# PIC32MZ1025W104132 register map
Vendor: Microchip
Registers are 32-bit, read-write, no defined reset value unless marked. A register's access mark holds for its fields unless they carry their own. Addresses are absolute, and some are shared; only a register's first bit layout is shown; [hi:lo] are bit positions; {n}, {i} and the like mark numbered series; 'fields as' and 'values as' point back to an identical list.

## TMR1
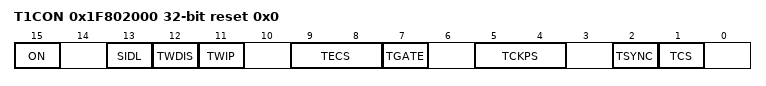
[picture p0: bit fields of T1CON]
0x1F802000 T1CON reset 0x0
  [15] ON, [13] SIDL, [12] TWDIS, [11] TWIP, [9:8] TECS, [7] TGATE, [5:4] TCKPS, [2] TSYNC, [1] TCS
0x1F802010 TMR1 reset 0x0
0x1F802020 PR1 reset 0xFFFF

## TMR2
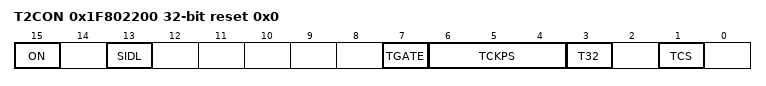
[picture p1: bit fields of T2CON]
0x1F802200 T2CON reset 0x0
  [15] ON, [13] SIDL, [7] TGATE, [6:4] TCKPS, [3] T32, [1] TCS
0x1F802210 TMR2 reset 0x0
0x1F802220 PR2 reset 0xFFFF

## TMR3
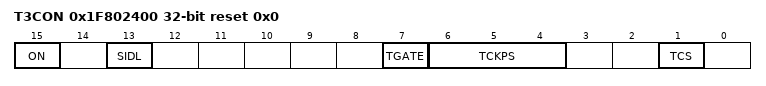
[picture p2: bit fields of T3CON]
0x1F802400 T3CON reset 0x0
  [15] ON, [13] SIDL, [7] TGATE, [6:4] TCKPS, [1] TCS
0x1F802410 TMR3 reset 0x0
0x1F802420 PR3 reset 0xFFFF

## TMR4
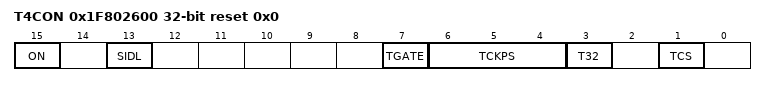
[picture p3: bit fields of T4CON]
0x1F802600 T4CON reset 0x0
  [15] ON, [13] SIDL, [7] TGATE, [6:4] TCKPS, [3] T32, [1] TCS
0x1F802610 TMR4 reset 0x0
0x1F802620 PR4 reset 0xFFFF

## TMR5
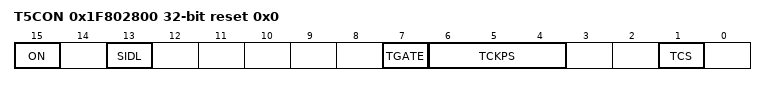
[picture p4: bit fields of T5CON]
0x1F802800 T5CON reset 0x0
  [15] ON, [13] SIDL, [7] TGATE, [6:4] TCKPS, [1] TCS
0x1F802810 TMR5 reset 0x0
0x1F802820 PR5 reset 0xFFFF

## TMR6
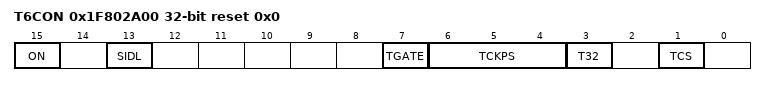
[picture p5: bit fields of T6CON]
0x1F802A00 T6CON reset 0x0
  [15] ON, [13] SIDL, [7] TGATE, [6:4] TCKPS, [3] T32, [1] TCS
0x1F802A10 TMR6 reset 0x0
0x1F802A20 PR6 reset 0xFFFF

## TMR7
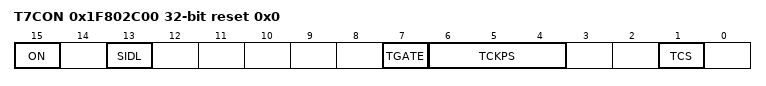
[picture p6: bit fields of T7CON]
0x1F802C00 T7CON reset 0x0
  [15] ON, [13] SIDL, [7] TGATE, [6:4] TCKPS, [1] TCS
0x1F802C10 TMR7 reset 0x0
0x1F802C20 PR7 reset 0xFFFF

## INT
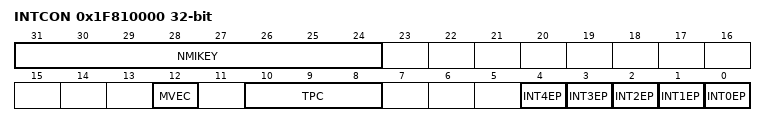
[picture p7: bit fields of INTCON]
0x1F810000 INTCON — (power-on value xxxxxxxx---------x-0-000---00000)
  [31:24] NMIKEY wo, [12] MVEC, [10:8] TPC, [n] INT{n}EP (n=0..4)
{0x1F810540+4i} OFF{i:03} reset 0x0 (i=0..24)
  [17:1] VOFF
{0x1F810540+4i} OFF{i:03} reset 0x0 (i=30..44)
  [17:1] VOFF
0x1F8105F4 OFF045 — (power-on value --------------xxxxxxxxxxxxxxxxx-)
  [17:1] VOFF
0x1F8105F8 OFF046 reset 0x0
  [17:1] VOFF
0x1F8105FC OFF047 reset 0x0
  [17:1] VOFF
{0x1F810540+4i} OFF{i:03} reset 0x0 (i=53..57)
  [17:1] VOFF
0x1F810628 OFF058 — (power-on value --------------xxxxxxxxxxxxxxxxx-)
  [17:1] VOFF
{0x1F810540+4i} OFF{i:03} reset 0x0 (i=59..64)
  [17:1] VOFF
{0x1F810540+4i} OFF{i:03} reset 0x0 (i=68..76)
  [17:1] VOFF
0x1F810680 OFF080 reset 0x0
  [17:1] VOFF
{0x1F810540+4i} OFF{i:03} reset 0x0 (i=83..92)
  [17:1] VOFF
{0x1F810540+4i} OFF{i:03} reset 0x0 (i=94..97)
  [17:1] VOFF
{0x1F810540+4i} OFF{i} reset 0x0 (i=100..104)
  [17:1] VOFF
{0x1F810540+4i} OFF{i} reset 0x0 (i=106..129)
  [17:1] VOFF
{0x1F810540+4i} OFF{i} reset 0x0 (i=142..145)
  [17:1] VOFF
0x1F810798 OFF150 reset 0x0
  [17:1] VOFF
{0x1F810540+4i} OFF{i} reset 0x0 (i=152..157)
  [17:1] VOFF
{0x1F810540+4i} OFF{i} reset 0x0 (i=162..168)
  [17:1] VOFF

## dma_bvci
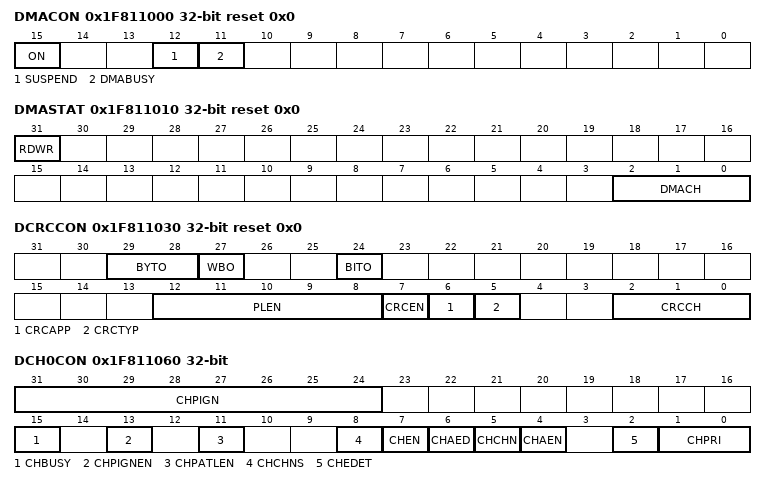
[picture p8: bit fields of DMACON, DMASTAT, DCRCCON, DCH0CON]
0x1F811000 DMACON reset 0x0
  [15] ON, [12] SUSPEND, [11] DMABUSY
0x1F811010 DMASTAT ro reset 0x0
  [31] RDWR, [2:0] DMACH
0x1F811020 DMAADDR ro reset 0x0
0x1F811030 DCRCCON reset 0x0
  [29:28] BYTO, [27] WBO, [24] BITO, [12:8] PLEN, [7] CRCEN, [6] CRCAPP, [5] CRCTYP, [2:0] CRCCH
0x1F811040 DCRCDATA reset 0x0
0x1F811050 DCRCXOR reset 0x0
0x1F811060 DCH0CON — (power-on value xxxxxxxx--------0-0-0--00000-000)
  [31:24] CHPIGN, [15] CHBUSY, [13] CHPIGNEN, [11] CHPATLEN, [8] CHCHNS, [7] CHEN, [6] CHAED, [5] CHCHN, [4] CHAEN, [2] CHEDET ro, [1:0] CHPRI
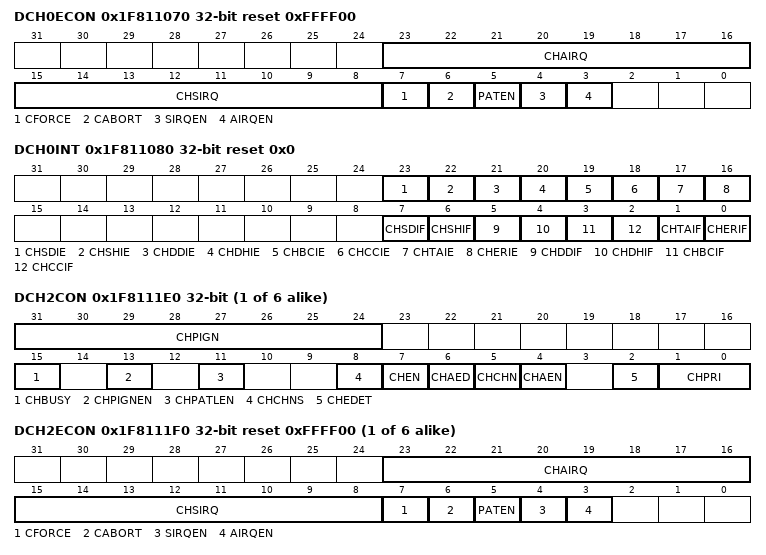
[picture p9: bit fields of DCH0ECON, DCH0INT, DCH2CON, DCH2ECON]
0x1F811070 DCH0ECON reset 0xFFFF00
  [23:16] CHAIRQ, [15:8] CHSIRQ, [7] CFORCE, [6] CABORT, [5] PATEN, [4] SIRQEN, [3] AIRQEN
0x1F811080 DCH0INT reset 0x0
  [23] CHSDIE, [22] CHSHIE, [21] CHDDIE, [20] CHDHIE, [19] CHBCIE, [18] CHCCIE, [17] CHTAIE, [16] CHERIE, [7] CHSDIF, [6] CHSHIF, [5] CHDDIF, [4] CHDHIF, [3] CHBCIF, [2] CHCCIF, [1] CHTAIF, [0] CHERIF
0x1F811090 DCH0SSA — (power-on value xxxxxxxxxxxxxxxxxxxxxxxxxxxxxxxx)
  [31:0] CHSSA
0x1F8110A0 DCH0DSA — (power-on value xxxxxxxxxxxxxxxxxxxxxxxxxxxxxxxx)
  [31:0] CHDSA
0x1F8110B0 DCH0SSIZ — (power-on value ----------------xxxxxxxxxxxxxxxx)
  [15:0] CHSSIZ
0x1F8110C0 DCH0DSIZ — (power-on value ----------------xxxxxxxxxxxxxxxx)
  [15:0] CHDSIZ
0x1F8110D0 DCH0SPTR reset 0x0
  [15:0] CHSPTR
0x1F8110E0 DCH0DPTR reset 0x0
  [15:0] CHDPTR
0x1F8110F0 DCH0CSIZ — (power-on value ----------------xxxxxxxxxxxxxxxx)
  [15:0] CHCSIZ
0x1F811100 DCH0CPTR reset 0x0
  [15:0] CHCPTR
0x1F811110 DCH0DAT — (power-on value ----------------xxxxxxxxxxxxxxxx)
  [15:0] CHPDAT
{0x1F811060+0xC0*i} DCH{i}CON (i=2..7) — (power-on value xxxxxxxx--------0-0-0--00000-000)
  fields as DCH0CON
{0x1F811070+0xC0*i} DCH{i}ECON reset 0xFFFF00 (i=2..7)
  fields as DCH0ECON
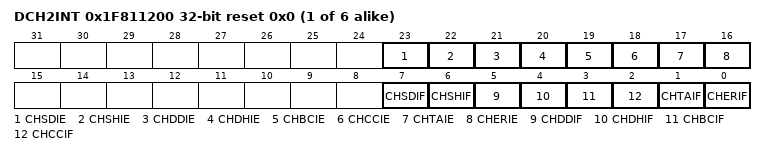
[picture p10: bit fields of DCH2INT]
{0x1F811080+0xC0*i} DCH{i}INT reset 0x0 (i=2..7)
  fields as DCH0INT
{0x1F811090+0xC0*i} DCH{i}SSA (i=2..7) — (power-on value xxxxxxxxxxxxxxxxxxxxxxxxxxxxxxxx)
  [31:0] CHSSA
{0x1F8110A0+0xC0*i} DCH{i}DSA (i=2..7) — (power-on value xxxxxxxxxxxxxxxxxxxxxxxxxxxxxxxx)
  [31:0] CHDSA
{0x1F8110B0+0xC0*i} DCH{i}SSIZ (i=2..7) — (power-on value ----------------xxxxxxxxxxxxxxxx)
  [15:0] CHSSIZ
{0x1F8110C0+0xC0*i} DCH{i}DSIZ (i=2..7) — (power-on value ----------------xxxxxxxxxxxxxxxx)
  [15:0] CHDSIZ
{0x1F8110D0+0xC0*i} DCH{i}SPTR reset 0x0 (i=2..7)
  [15:0] CHSPTR
{0x1F8110E0+0xC0*i} DCH{i}DPTR reset 0x0 (i=2..7)
  [15:0] CHDPTR
{0x1F8110F0+0xC0*i} DCH{i}CSIZ (i=2..7) — (power-on value ----------------xxxxxxxxxxxxxxxx)
  [15:0] CHCSIZ
{0x1F811100+0xC0*i} DCH{i}CPTR reset 0x0 (i=2..7)
  [15:0] CHCPTR
{0x1F811110+0xC0*i} DCH{i}DAT (i=2..7) — (power-on value ----------------xxxxxxxxxxxxxxxx)
  [15:0] CHPDAT
